# iostm32f205zx register map
Registers are 32-bit, access not given, no defined reset value unless marked. A register's access mark holds for its fields unless they carry their own. Addresses are absolute; registers are grouped by the start of their names; [hi:lo] are bit positions; {n}, {i} and the like mark numbered series.

## USART3
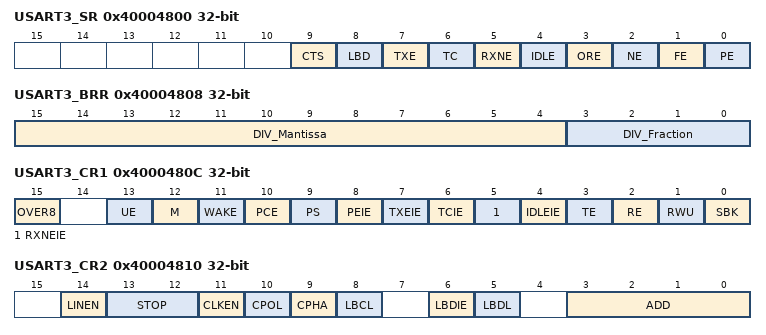
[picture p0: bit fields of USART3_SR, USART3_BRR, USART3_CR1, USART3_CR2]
0x40004800 USART3_SR
  [9] CTS, [8] LBD, [7] TXE, [6] TC, [5] RXNE, [4] IDLE, [3] ORE, [2] NE, [1] FE, [0] PE
0x40004804 USART3_DR
  [8:0] DR
0x40004808 USART3_BRR
  [15:4] DIV_Mantissa, [3:0] DIV_Fraction
0x4000480C USART3_CR1
  [15] OVER8, [13] UE, [12] M, [11] WAKE, [10] PCE, [9] PS, [8] PEIE, [7] TXEIE, [6] TCIE, [5] RXNEIE, [4] IDLEIE, [3] TE, [2] RE, [1] RWU, [0] SBK
0x40004810 USART3_CR2
  [14] LINEN, [13:12] STOP, [11] CLKEN, [10] CPOL, [9] CPHA, [8] LBCL, [6] LBDIE, [5] LBDL, [3:0] ADD
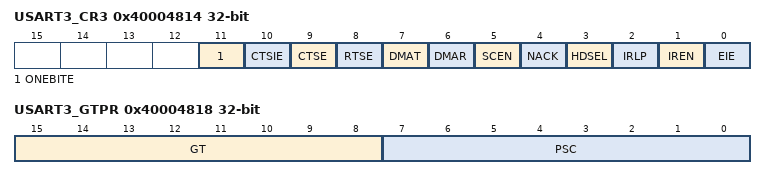
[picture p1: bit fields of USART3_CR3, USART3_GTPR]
0x40004814 USART3_CR3
  [11] ONEBITE, [10] CTSIE, [9] CTSE, [8] RTSE, [7] DMAT, [6] DMAR, [5] SCEN, [4] NACK, [3] HDSEL, [2] IRLP, [1] IREN, [0] EIE
0x40004818 USART3_GTPR
  [15:8] GT, [7:0] PSC

## UART4
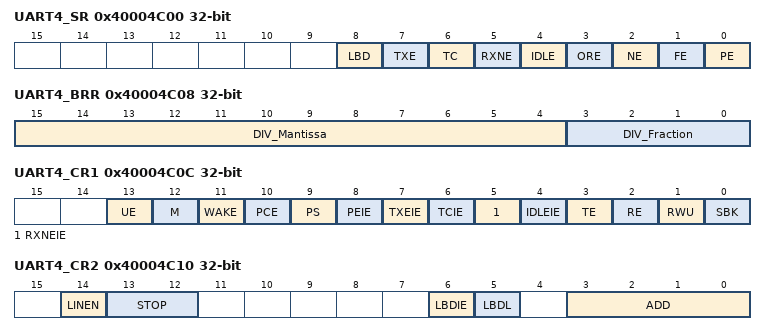
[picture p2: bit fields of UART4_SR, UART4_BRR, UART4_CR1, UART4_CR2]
0x40004C00 UART4_SR
  [8] LBD, [7] TXE, [6] TC, [5] RXNE, [4] IDLE, [3] ORE, [2] NE, [1] FE, [0] PE
0x40004C04 UART4_DR
  [8:0] DR
0x40004C08 UART4_BRR
  [15:4] DIV_Mantissa, [3:0] DIV_Fraction
0x40004C0C UART4_CR1
  [13] UE, [12] M, [11] WAKE, [10] PCE, [9] PS, [8] PEIE, [7] TXEIE, [6] TCIE, [5] RXNEIE, [4] IDLEIE, [3] TE, [2] RE, [1] RWU, [0] SBK
0x40004C10 UART4_CR2
  [14] LINEN, [13:12] STOP, [6] LBDIE, [5] LBDL, [3:0] ADD
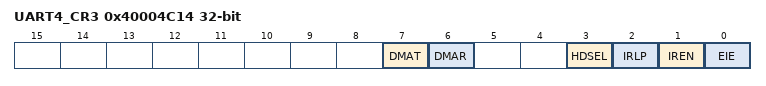
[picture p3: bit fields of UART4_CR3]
0x40004C14 UART4_CR3
  [7] DMAT, [6] DMAR, [3] HDSEL, [2] IRLP, [1] IREN, [0] EIE

## UART5
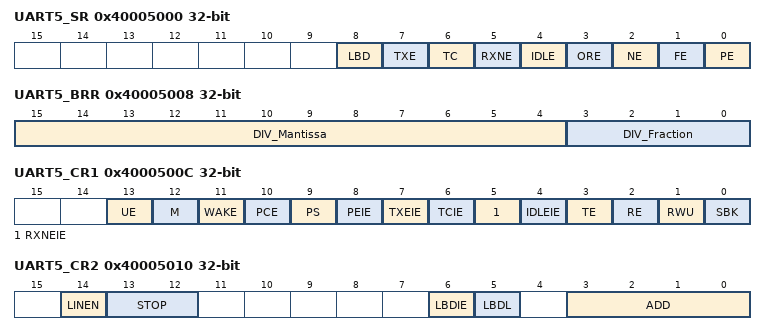
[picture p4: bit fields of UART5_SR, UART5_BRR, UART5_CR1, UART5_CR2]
0x40005000 UART5_SR
  [8] LBD, [7] TXE, [6] TC, [5] RXNE, [4] IDLE, [3] ORE, [2] NE, [1] FE, [0] PE
0x40005004 UART5_DR
  [8:0] DR
0x40005008 UART5_BRR
  [15:4] DIV_Mantissa, [3:0] DIV_Fraction
0x4000500C UART5_CR1
  [13] UE, [12] M, [11] WAKE, [10] PCE, [9] PS, [8] PEIE, [7] TXEIE, [6] TCIE, [5] RXNEIE, [4] IDLEIE, [3] TE, [2] RE, [1] RWU, [0] SBK
0x40005010 UART5_CR2
  [14] LINEN, [13:12] STOP, [6] LBDIE, [5] LBDL, [3:0] ADD
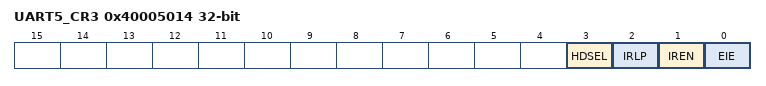
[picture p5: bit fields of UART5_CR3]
0x40005014 UART5_CR3
  [3] HDSEL, [2] IRLP, [1] IREN, [0] EIE

## USART6
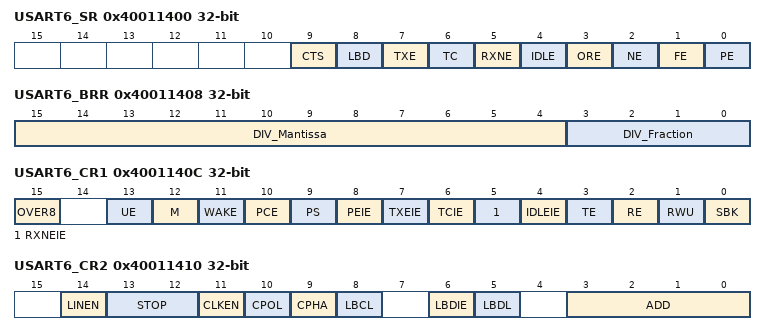
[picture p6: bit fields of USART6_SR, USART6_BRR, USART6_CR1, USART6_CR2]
0x40011400 USART6_SR
  [9] CTS, [8] LBD, [7] TXE, [6] TC, [5] RXNE, [4] IDLE, [3] ORE, [2] NE, [1] FE, [0] PE
0x40011404 USART6_DR
  [8:0] DR
0x40011408 USART6_BRR
  [15:4] DIV_Mantissa, [3:0] DIV_Fraction
0x4001140C USART6_CR1
  [15] OVER8, [13] UE, [12] M, [11] WAKE, [10] PCE, [9] PS, [8] PEIE, [7] TXEIE, [6] TCIE, [5] RXNEIE, [4] IDLEIE, [3] TE, [2] RE, [1] RWU, [0] SBK
0x40011410 USART6_CR2
  [14] LINEN, [13:12] STOP, [11] CLKEN, [10] CPOL, [9] CPHA, [8] LBCL, [6] LBDIE, [5] LBDL, [3:0] ADD
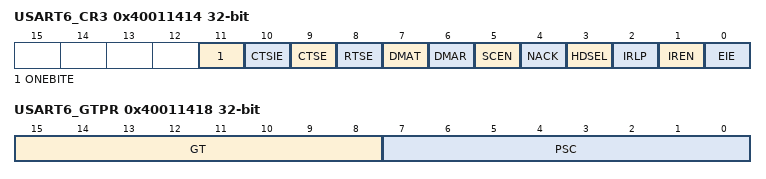
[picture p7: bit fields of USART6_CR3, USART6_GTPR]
0x40011414 USART6_CR3
  [11] ONEBITE, [10] CTSIE, [9] CTSE, [8] RTSE, [7] DMAT, [6] DMAR, [5] SCEN, [4] NACK, [3] HDSEL, [2] IRLP, [1] IREN, [0] EIE
0x40011418 USART6_GTPR
  [15:8] GT, [7:0] PSC

## ADC
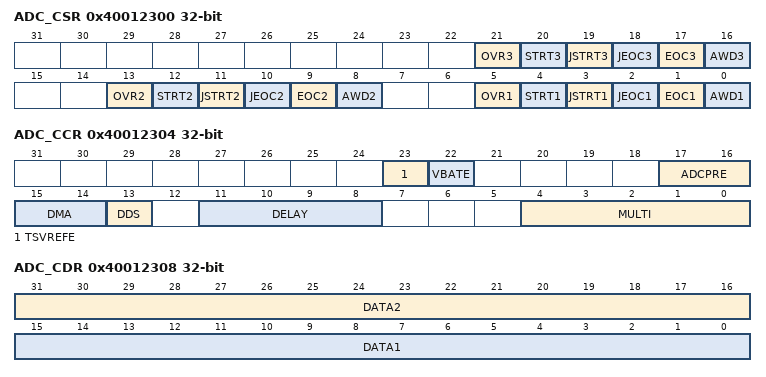
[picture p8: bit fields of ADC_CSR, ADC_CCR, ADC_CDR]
0x40012300 ADC_CSR
  [21] OVR3, [20] STRT3, [19] JSTRT3, [18] JEOC3, [17] EOC3, [16] AWD3, [13] OVR2, [12] STRT2, [11] JSTRT2, [10] JEOC2, [9] EOC2, [8] AWD2, [5] OVR1, [4] STRT1, [3] JSTRT1, [2] JEOC1, [1] EOC1, [0] AWD1
0x40012304 ADC_CCR
  [23] TSVREFE, [22] VBATE, [17:16] ADCPRE, [15:14] DMA, [13] DDS, [11:8] DELAY, [4:0] MULTI
0x40012308 ADC_CDR
  [31:16] DATA2, [15:0] DATA1

## ADC1
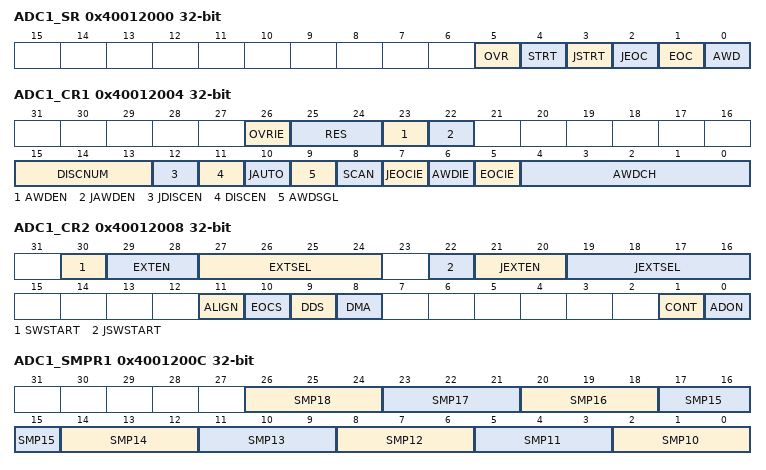
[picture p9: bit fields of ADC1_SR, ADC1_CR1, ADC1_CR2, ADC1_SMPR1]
0x40012000 ADC1_SR
  [5] OVR, [4] STRT, [3] JSTRT, [2] JEOC, [1] EOC, [0] AWD
0x40012004 ADC1_CR1
  [26] OVRIE, [25:24] RES, [23] AWDEN, [22] JAWDEN, [15:13] DISCNUM, [12] JDISCEN, [11] DISCEN, [10] JAUTO, [9] AWDSGL, [8] SCAN, [7] JEOCIE, [6] AWDIE, [5] EOCIE, [4:0] AWDCH
0x40012008 ADC1_CR2
  [30] SWSTART, [29:28] EXTEN, [27:24] EXTSEL, [22] JSWSTART, [21:20] JEXTEN, [19:16] JEXTSEL, [11] ALIGN, [10] EOCS, [9] DDS, [8] DMA, [1] CONT, [0] ADON
0x4001200C ADC1_SMPR1
  [3n-28:3n-30] SMP{n} (n=10..18)
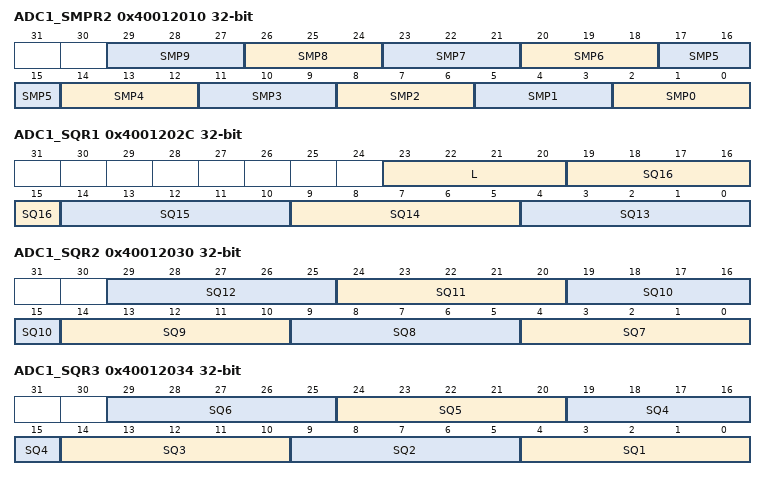
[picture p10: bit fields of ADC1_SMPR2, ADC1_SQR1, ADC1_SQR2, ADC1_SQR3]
0x40012010 ADC1_SMPR2
  [3n+2:3n] SMP{n} (n=0..9)
{0x40012010+4i} ADC1_JOFR{i} (i=1..4)
  [11:0] JOFFSET
0x40012024 ADC1_HTR
  [11:0] HT
0x40012028 ADC1_LTR
  [11:0] LT
0x4001202C ADC1_SQR1
  [23:20] L, [5n-61:5n-65] SQ{n} (n=13..16)
0x40012030 ADC1_SQR2
  [5n-31:5n-35] SQ{n} (n=7..12)
0x40012034 ADC1_SQR3
  [5n-1:5n-5] SQ{n} (n=1..6)
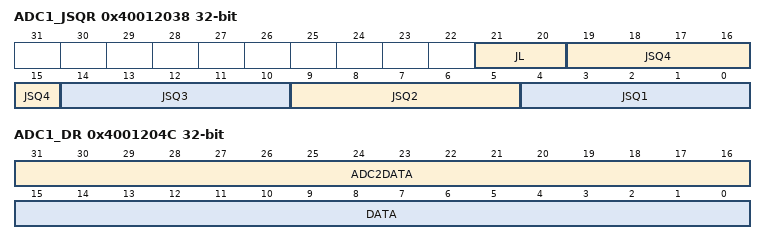
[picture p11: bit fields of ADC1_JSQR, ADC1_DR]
0x40012038 ADC1_JSQR
  [21:20] JL, [5n-1:5n-5] JSQ{n} (n=1..4)
{0x40012038+4i} ADC1_JDR{i} (i=1..4)
  [15:0] JDATA
0x4001204C ADC1_DR
  [31:16] ADC2DATA, [15:0] DATA
